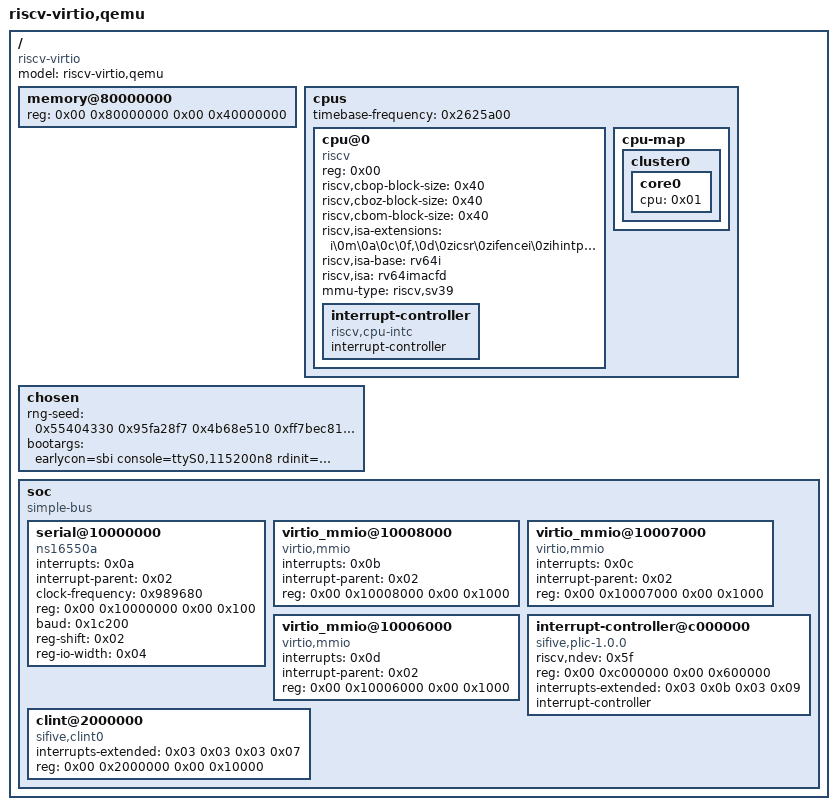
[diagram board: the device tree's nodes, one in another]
/dts-v1/;

/ {
	#address-cells = <0x02>;
	#size-cells = <0x02>;
	compatible = "riscv-virtio";
	model = "riscv-virtio,qemu";

	memory@80000000 {
		device_type = "memory";
		reg = <0x00 0x80000000 0x00 0x40000000>;
	};

	cpus {
		#address-cells = <0x01>;
		#size-cells = <0x00>;
		timebase-frequency = <0x2625a00>;

		cpu@0 {
			phandle = <0x01>;
			device_type = "cpu";
			reg = <0x00>;
			status = "okay";
			compatible = "riscv";
			riscv,cbop-block-size = <0x40>;
			riscv,cboz-block-size = <0x40>;
			riscv,cbom-block-size = <0x40>;
			riscv,isa-extensions = "i\0m\0a\0c\0f,\0d\0zicsr\0zifencei\0zihintpause\0zca\0zcb\0zcd\0zba\0zbb\0zbc\0zbs\0zicbom\0zicboz\0zicbop\0sswi\0sstc\0snvi\0stsp\0svinval";
			riscv,isa-base = "rv64i";
			riscv,isa = "rv64imacfd";
			mmu-type = "riscv,sv39";

			interrupt-controller {
				#interrupt-cells = <0x01>;
				interrupt-controller;
				compatible = "riscv,cpu-intc";
				phandle = <0x03>;
			};
		};

		cpu-map {

			cluster0 {

				core0 {
					cpu = <0x01>;
				};
			};
		};
	};

	chosen {
		rng-seed = <0x55404330 0x95fa28f7 0x4b68e510 0xff7bec81 0xffe0df4d 0x9d97558 0x42719e74 0xb6f0ec>;
		bootargs = "earlycon=sbi console=ttyS0,115200n8 rdinit=/sbin/init";
	};

	soc {
		#address-cells = <0x02>;
		#size-cells = <0x02>;
		compatible = "simple-bus";
		ranges;

		serial@10000000 {
			interrupts = <0x0a>;
			interrupt-parent = <0x02>;
			clock-frequency = <0x989680>;
			reg = <0x00 0x10000000 0x00 0x100>;
			baud = <0x1c200>;
			reg-shift = <0x02>;
			reg-io-width = <0x04>;
			compatible = "ns16550a";
		};

		virtio_mmio@10008000 {
			interrupts = <0x0b>;
			interrupt-parent = <0x02>;
			reg = <0x00 0x10008000 0x00 0x1000>;
			compatible = "virtio,mmio";
		};

		virtio_mmio@10007000 {
			interrupts = <0x0c>;
			interrupt-parent = <0x02>;
			reg = <0x00 0x10007000 0x00 0x1000>;
			compatible = "virtio,mmio";
		};

		virtio_mmio@10006000 {
			interrupts = <0x0d>;
			interrupt-parent = <0x02>;
			reg = <0x00 0x10006000 0x00 0x1000>;
			compatible = "virtio,mmio";
		};

		interrupt-controller@c000000 {
			riscv,ndev = <0x5f>;
			reg = <0x00 0xc000000 0x00 0x600000>;
			interrupts-extended = <0x03 0x0b 0x03 0x09>;
			interrupt-controller;
			compatible = "sifive,plic-1.0.0\0riscv,plic0";
			#address-cells = <0x00>;
			#interrupt-cells = <0x01>;
			phandle = <0x02>;
		};

		clint@2000000 {
			interrupts-extended = <0x03 0x03 0x03 0x07>;
			reg = <0x00 0x2000000 0x00 0x10000>;
			compatible = "sifive,clint0\0riscv,clint0";
		};
	};
};
